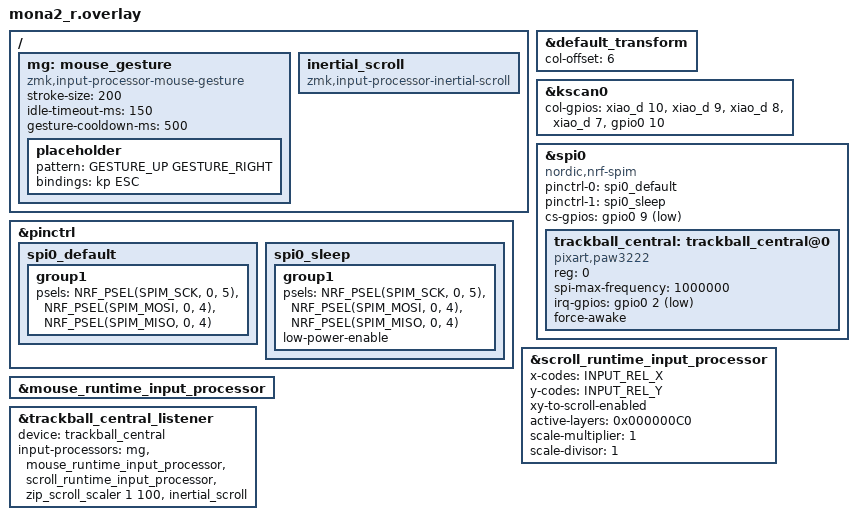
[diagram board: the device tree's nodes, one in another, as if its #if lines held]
#include "mona2.dtsi"
/* mona2.dtsi 内で RC(row,col) のマトリクス展開が終わった後に include する
   (runtime-input-processor.dtsi が modifiers.h 経由で RC(keycode) を再定義するため) */
#include <input/processors/runtime-input-processor.dtsi>
#include <input/processors.dtsi>
#include <zephyr/dt-bindings/input/input-event-codes.h>
#include <dt-bindings/zmk/mouse-gesture.h>

&default_transform {
    col-offset = <6>;
};

&kscan0 {
    col-gpios
        = <&xiao_d 10 GPIO_ACTIVE_HIGH>
        , <&xiao_d 9 GPIO_ACTIVE_HIGH>
        , <&xiao_d 8 GPIO_ACTIVE_HIGH>
        , <&xiao_d 7 GPIO_ACTIVE_HIGH>
        , <&gpio0 10 GPIO_ACTIVE_HIGH>
        ;
};

&pinctrl {
    spi0_default: spi0_default {
        group1 {
            psels = <NRF_PSEL(SPIM_SCK, 0, 5)>,
                <NRF_PSEL(SPIM_MOSI, 0, 4)>,
                <NRF_PSEL(SPIM_MISO, 0, 4)>;
        };
    };

    spi0_sleep: spi0_sleep {
        group1 {
            psels = <NRF_PSEL(SPIM_SCK, 0, 5)>,
                <NRF_PSEL(SPIM_MOSI, 0, 4)>,
                <NRF_PSEL(SPIM_MISO, 0, 4)>;
            low-power-enable;
        };
    };
};

&spi0 {
    status = "okay";
    compatible = "nordic,nrf-spim";
    pinctrl-0 = <&spi0_default>;
    pinctrl-1 = <&spi0_sleep>;
    pinctrl-names = "default", "sleep";
    cs-gpios = <&gpio0 9 GPIO_ACTIVE_LOW>;

    trackball_central: trackball_central@0 {
        status = "okay";
#ifdef CONFIG_TRACKBALL_PAW3222
        compatible = "pixart,paw3222";
        reg = <0>;
        spi-max-frequency = <1000000>;
        irq-gpios = <&gpio0 2 (GPIO_ACTIVE_LOW | GPIO_PULL_UP)>;
        force-awake;
#else /* default: PMW3610 */
        /* cormoran さんの custom Studio RPC 対応 PMW3610 ドライバ。
           DYA Studio の「トラックボールセンサー」診断タブがこれを要求する。
           (Zephyr 4.1 が純正 "pixart,pmw3610" ドライバを取り込んだため、
            そもそも旧 compatible "pixart,pmw3610" はもう使えない。)

           軸の反転は devicetree ではなく
           CONFIG_PMW3610_SWAP_XY / _INVERT_X / _INVERT_Y で指定する。
           DYA Studio から実行時にも変更できる (mona2_r.conf 参照)。 */
        compatible = "cormoran,pmw3610";
        reg = <0>;
        spi-max-frequency = <2000000>;
        irq-gpios = <&gpio0 2 (GPIO_ACTIVE_LOW | GPIO_PULL_UP)>;
        cpi = <600>;
        evt-type = <INPUT_EV_REL>;
        x-input-code = <INPUT_REL_X>;
        y-input-code = <INPUT_REL_Y>;
        /* DYA Studio 上でこのセンサーを識別するための短い ID */
        settings-id = "tball";
#endif
    };
};

/* ─────────────────────────────────────────────────────────────
   scroll_runtime_input_processor をスクロール変換器として上書き
   ────────────────────────────────────────────────────── */
&scroll_runtime_input_processor {
    x-codes = <INPUT_REL_X>;
    y-codes = <INPUT_REL_Y>;
    xy-to-scroll-enabled;
    active-layers = <0x000000C0>; /* layer6 + layer7 */
    scale-multiplier = <1>;
    scale-divisor = <1>;   /* Studio UI の倍率がそのまま実効値 (1.0x基準)。固定減速は listener 側 zip_scroll_scaler */
};

&mouse_runtime_input_processor {
};

/* ─────────────────────────────────────────────────────────────
   kot149 mouse-gesture input processor (Phase 5)
   トップレベルの新規ノードなので `/ { ... }` で包む
   ────────────────────────────────────────────────────── */
/ {
    mg: mouse_gesture {
        compatible = "zmk,input-processor-mouse-gesture";
        #input-processor-cells = <0>;
        /* Activate only while &mg_set is held so normal mouse/scroll layers do not trigger gestures. */
        stroke-size = <200>;
        idle-timeout-ms = <150>;
        gesture-cooldown-ms = <500>;

        placeholder {
            pattern = <GESTURE_UP GESTURE_RIGHT>;
            bindings = <&kp ESC>;
        };
    };
    inertial_scroll: inertial_scroll {
        compatible = "zmk,input-processor-inertial-scroll";
        status = "okay";
        #input-processor-cells = <0>;
    };

};

&trackball_central_listener {
    status = "okay";
    device = <&trackball_central>;
    input-processors = <&mg &mouse_runtime_input_processor &scroll_runtime_input_processor &zip_scroll_scaler 1 100 &inertial_scroll>;
};
